AUTOSAR XML (schema 00048)
package /MICROSAR/NvM_swc/DataTypes
  impl type NvM_RequestResultType: compu {0=NVM_REQ_OK, 1=NVM_REQ_NOT_OK, 2=NVM_REQ_PENDING, 3=NVM_REQ_INTEGRITY_FAILED, 4=NVM_REQ_BLOCK_SKIPPED, 5=NVM_REQ_NV_INVALIDATED, 6=NVM_REQ_CANCELED, 7=NVM_REQ_REDUNDANCY_FAILED, 8=NVM_REQ_RESTORED_FROM_ROM}, range raw 0..8, implementation-data-type=uint8
  impl type NvM_BlockIdType: range raw 1..32767, implementation-data-type=uint16
  impl type NvM_ServiceIdType: compu {6=NVM_READ_BLOCK, 7=NVM_WRITE_BLOCK, 8=NVM_RESTORE_BLOCK_DEFAULTS, 9=NVM_ERASE_BLOCK, 11=NVM_INVALIDATE_NV_BLOCK, 12=NVM_READ_ALL}, range raw 6..12, implementation-data-type=uint8
package /MICROSAR/NvM_swc/Interfaces
  client server interface NvMAdministration: is-service=true, service-kind=NON-VOLATILE-RAM-MANAGER
    operation SetBlockProtection: possible-error=NvMAdministration/E_NOT_OK
      arg ProtectionEnabled: type=boolean, direction=IN
    error E_NOT_OK: error-code=1
  client server interface NvMService_AC3_SRBS: is-service=true, service-kind=NON-VOLATILE-RAM-MANAGER
    6 x operation, all with possible-error=NvMService_AC3_SRBS/E_NOT_OK:
      GetErrorStatus
        arg ErrorStatus: type=NvM_RequestResultType, direction=OUT
      SetRamBlockStatus
        arg RamBlockStatus: type=boolean, direction=IN
      ReadBlock
        arg DstPtr: type=dtRef_VOID, direction=IN
      WriteBlock
        arg SrcPtr: type=dtRef_const_VOID, direction=IN
      InvalidateNvBlock
      EraseBlock
    error E_NOT_OK: error-code=1
  client server interface NvMNotifyJobFinished: is-service=true, service-kind=NON-VOLATILE-RAM-MANAGER
    operation JobFinished
      arg ServiceId: type=NvM_ServiceIdType, direction=IN
      arg JobResult: type=NvM_RequestResultType, direction=IN
package /MICROSAR/NvM_swc/ComponentTypes
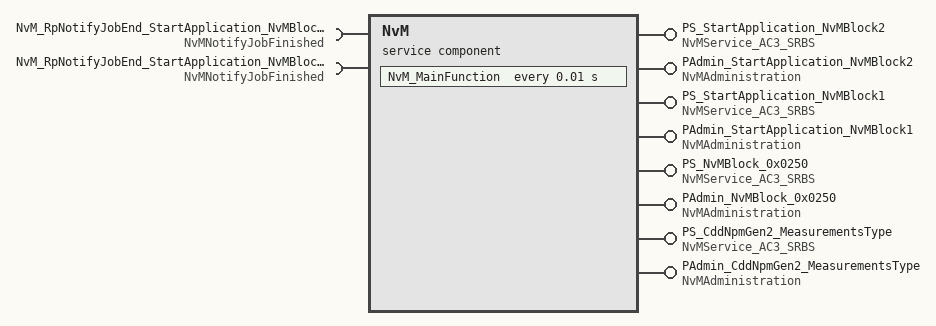
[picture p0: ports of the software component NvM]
  service sw component type NvM: category=SERVICE_COMPONENT
    provide port PS_StartApplication_NvMBlock2: provided-interface=NvMService_AC3_SRBS
    provide port PAdmin_StartApplication_NvMBlock2: provided-interface=NvMAdministration
    require port NvM_RpNotifyJobEnd_StartApplication_NvMBlock2: required-interface=NvMNotifyJobFinished
    provide port PS_StartApplication_NvMBlock1: provided-interface=NvMService_AC3_SRBS
    provide port PAdmin_StartApplication_NvMBlock1: provided-interface=NvMAdministration
    require port NvM_RpNotifyJobEnd_StartApplication_NvMBlock1: required-interface=NvMNotifyJobFinished
    4 x provide port:
      PS_NvMBlock_0x0250: provided-interface=NvMService_AC3_SRBS
      PAdmin_NvMBlock_0x0250: provided-interface=NvMAdministration
      PS_CddNpmGen2_MeasurementsType: provided-interface=NvMService_AC3_SRBS
      PAdmin_CddNpmGen2_MeasurementsType: provided-interface=NvMAdministration
    behavior NvMInternalBehavior: handle-termination-and-restart=NO-SUPPORT
      timing event Timer_NvM_MainFunction: start-on-event=NvM_MainFunction, period=0.01
      28 x operation invoked event:
        OpEventGetErrorStatus_GetErrorStatus_PS_StartApplication_NvMBlock2: start-on-event=GetErrorStatus, operation=PS_StartApplication_NvMBlock2.GetErrorStatus
        OpEventGetErrorStatus_GetErrorStatus_PS_StartApplication_NvMBlock1: start-on-event=GetErrorStatus, operation=PS_StartApplication_NvMBlock1.GetErrorStatus
        OpEventGetErrorStatus_GetErrorStatus_PS_NvMBlock_0x0250: start-on-event=GetErrorStatus, operation=PS_NvMBlock_0x0250.GetErrorStatus
        OpEventGetErrorStatus_GetErrorStatus_PS_CddNpmGen2_MeasurementsType: start-on-event=GetErrorStatus, operation=PS_CddNpmGen2_MeasurementsType.GetErrorStatus
        OpEventSetRamBlockStatus_SetRamBlockStatus_PS_StartApplication_NvMBlock2: start-on-event=SetRamBlockStatus, operation=PS_StartApplication_NvMBlock2.SetRamBlockStatus
        OpEventSetRamBlockStatus_SetRamBlockStatus_PS_StartApplication_NvMBlock1: start-on-event=SetRamBlockStatus, operation=PS_StartApplication_NvMBlock1.SetRamBlockStatus
        OpEventSetRamBlockStatus_SetRamBlockStatus_PS_NvMBlock_0x0250: start-on-event=SetRamBlockStatus, operation=PS_NvMBlock_0x0250.SetRamBlockStatus
        OpEventSetRamBlockStatus_SetRamBlockStatus_PS_CddNpmGen2_MeasurementsType: start-on-event=SetRamBlockStatus, operation=PS_CddNpmGen2_MeasurementsType.SetRamBlockStatus
        OpEventReadBlock_ReadBlock_PS_StartApplication_NvMBlock2: start-on-event=ReadBlock, operation=PS_StartApplication_NvMBlock2.ReadBlock
        OpEventReadBlock_ReadBlock_PS_StartApplication_NvMBlock1: start-on-event=ReadBlock, operation=PS_StartApplication_NvMBlock1.ReadBlock
        OpEventReadBlock_ReadBlock_PS_NvMBlock_0x0250: start-on-event=ReadBlock, operation=PS_NvMBlock_0x0250.ReadBlock
        OpEventReadBlock_ReadBlock_PS_CddNpmGen2_MeasurementsType: start-on-event=ReadBlock, operation=PS_CddNpmGen2_MeasurementsType.ReadBlock
        OpEventWriteBlock_WriteBlock_PS_StartApplication_NvMBlock2: start-on-event=WriteBlock, operation=PS_StartApplication_NvMBlock2.WriteBlock
        OpEventWriteBlock_WriteBlock_PS_StartApplication_NvMBlock1: start-on-event=WriteBlock, operation=PS_StartApplication_NvMBlock1.WriteBlock
        OpEventWriteBlock_WriteBlock_PS_NvMBlock_0x0250: start-on-event=WriteBlock, operation=PS_NvMBlock_0x0250.WriteBlock
        OpEventWriteBlock_WriteBlock_PS_CddNpmGen2_MeasurementsType: start-on-event=WriteBlock, operation=PS_CddNpmGen2_MeasurementsType.WriteBlock
        OpEventInvalidateNvBlock_InvalidateNvBlock_PS_StartApplication_NvMBlock2: start-on-event=InvalidateNvBlock, operation=PS_StartApplication_NvMBlock2.InvalidateNvBlock
        OpEventInvalidateNvBlock_InvalidateNvBlock_PS_StartApplication_NvMBlock1: start-on-event=InvalidateNvBlock, operation=PS_StartApplication_NvMBlock1.InvalidateNvBlock
        OpEventInvalidateNvBlock_InvalidateNvBlock_PS_NvMBlock_0x0250: start-on-event=InvalidateNvBlock, operation=PS_NvMBlock_0x0250.InvalidateNvBlock
        OpEventInvalidateNvBlock_InvalidateNvBlock_PS_CddNpmGen2_MeasurementsType: start-on-event=InvalidateNvBlock, operation=PS_CddNpmGen2_MeasurementsType.InvalidateNvBlock
        OpEventEraseBlock_EraseBlock_PS_StartApplication_NvMBlock2: start-on-event=EraseBlock, operation=PS_StartApplication_NvMBlock2.EraseBlock
        OpEventEraseBlock_EraseBlock_PS_StartApplication_NvMBlock1: start-on-event=EraseBlock, operation=PS_StartApplication_NvMBlock1.EraseBlock
        OpEventEraseBlock_EraseBlock_PS_NvMBlock_0x0250: start-on-event=EraseBlock, operation=PS_NvMBlock_0x0250.EraseBlock
        OpEventEraseBlock_EraseBlock_PS_CddNpmGen2_MeasurementsType: start-on-event=EraseBlock, operation=PS_CddNpmGen2_MeasurementsType.EraseBlock
        OpEventSetBlockProtection_SetBlockProtection_PAdmin_StartApplication_NvMBlock2: start-on-event=SetBlockProtection, operation=PAdmin_StartApplication_NvMBlock2.SetBlockProtection
        OpEventSetBlockProtection_SetBlockProtection_PAdmin_StartApplication_NvMBlock1: start-on-event=SetBlockProtection, operation=PAdmin_StartApplication_NvMBlock1.SetBlockProtection
        OpEventSetBlockProtection_SetBlockProtection_PAdmin_NvMBlock_0x0250: start-on-event=SetBlockProtection, operation=PAdmin_NvMBlock_0x0250.SetBlockProtection
        OpEventSetBlockProtection_SetBlockProtection_PAdmin_CddNpmGen2_MeasurementsType: start-on-event=SetBlockProtection, operation=PAdmin_CddNpmGen2_MeasurementsType.SetBlockProtection
      port-api-options:
        {enable-take-address=true, indirect-api=false, port-defined-argument-value{value=4, value-type=NvM_BlockIdType}, port=PS_StartApplication_NvMBlock2}
        {enable-take-address=true, indirect-api=false, port-defined-argument-value{value=4, value-type=NvM_BlockIdType}, port=PAdmin_StartApplication_NvMBlock2}
        enable-take-address=true, indirect-api=false, port=NvM_RpNotifyJobEnd_StartApplication_NvMBlock2
        {enable-take-address=true, indirect-api=false, port-defined-argument-value{value=5, value-type=NvM_BlockIdType}, port=PS_StartApplication_NvMBlock1}
        {enable-take-address=true, indirect-api=false, port-defined-argument-value{value=5, value-type=NvM_BlockIdType}, port=PAdmin_StartApplication_NvMBlock1}
        enable-take-address=true, indirect-api=false, port=NvM_RpNotifyJobEnd_StartApplication_NvMBlock1
        {enable-take-address=true, indirect-api=false, port-defined-argument-value{value=24, value-type=NvM_BlockIdType}, port=PS_NvMBlock_0x0250}
        {enable-take-address=true, indirect-api=false, port-defined-argument-value{value=24, value-type=NvM_BlockIdType}, port=PAdmin_NvMBlock_0x0250}
        {enable-take-address=true, indirect-api=false, port-defined-argument-value{value=25, value-type=NvM_BlockIdType}, port=PS_CddNpmGen2_MeasurementsType}
        {enable-take-address=true, indirect-api=false, port-defined-argument-value{value=25, value-type=NvM_BlockIdType}, port=PAdmin_CddNpmGen2_MeasurementsType}
      8 x runnable:
        NvM_MainFunction
          sync call OpServerCallNvM_MainFunction_JobFinished_NvM_RpNotifyJobEnd_StartApplication_NvMBlock2: operation=NvM_RpNotifyJobEnd_StartApplication_NvMBlock2.JobFinished, timeout=0
          sync call OpServerCallNvM_MainFunction_JobFinished_NvM_RpNotifyJobEnd_StartApplication_NvMBlock1: operation=NvM_RpNotifyJobEnd_StartApplication_NvMBlock1.JobFinished, timeout=0
        GetErrorStatus: can-be-invoked-concurrently=true, symbol=NvM_GetErrorStatus
        SetRamBlockStatus: can-be-invoked-concurrently=true, symbol=NvM_SetRamBlockStatus
        ReadBlock: can-be-invoked-concurrently=true, symbol=NvM_ReadBlock
        WriteBlock: can-be-invoked-concurrently=true, symbol=NvM_WriteBlock
        InvalidateNvBlock: can-be-invoked-concurrently=true, symbol=NvM_InvalidateNvBlock
        EraseBlock: can-be-invoked-concurrently=true, symbol=NvM_EraseNvBlock
        SetBlockProtection: can-be-invoked-concurrently=true, symbol=NvM_SetBlockProtection
  swc implementation NvMImplementation: programming-language=C, behavior=NvMInternalBehavior
